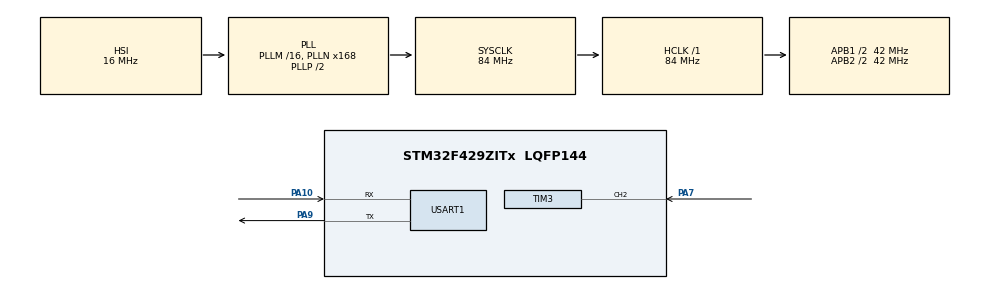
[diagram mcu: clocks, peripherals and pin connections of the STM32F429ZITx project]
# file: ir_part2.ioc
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Mcu.Family=STM32F4
Mcu.Name=STM32F429ZITx
Mcu.Package=LQFP144
NVIC.PriorityGroup=NVIC_PRIORITYGROUP_4
NVIC.TIM3_IRQn=true\:0\:0\:false\:false\:true\:true\:true
PA10.Mode=Asynchronous
PA10.Signal=USART1_RX
PA7.Signal=S_TIM3_CH2
PA9.Mode=Asynchronous
PA9.Signal=USART1_TX
ProjectManager.HeapSize=0x200
ProjectManager.StackSize=0x400
ProjectManager.TargetToolchain=MDK-ARM V5
RCC.48MHZClocksFreq_Value=42000000
RCC.AHBFreq_Value=84000000
RCC.APB1CLKDivider=RCC_HCLK_DIV2
RCC.APB1Freq_Value=42000000
RCC.APB1TimFreq_Value=84000000
RCC.APB2CLKDivider=RCC_HCLK_DIV2
RCC.APB2Freq_Value=42000000
RCC.APB2TimFreq_Value=84000000
RCC.CortexFreq_Value=84000000
RCC.HCLKFreq_Value=84000000
RCC.HSE_VALUE=25000000
RCC.HSI_VALUE=16000000
RCC.LSE_VALUE=32768
RCC.PLLN=168
RCC.SYSCLKFreq_VALUE=84000000
RCC.SYSCLKSource=RCC_SYSCLKSOURCE_PLLCLK
RCC.VCOOutputFreq_Value=168000000
SH.S_TIM3_CH2.0=TIM3_CH2,Input_Capture2_from_TI2
TIM3.Channel-Input_Capture2_from_TI2=TIM_CHANNEL_2
TIM3.ICPolarity_CH2=TIM_INPUTCHANNELPOLARITY_BOTHEDGE
TIM3.Period=65535
TIM3.Prescaler=83
TIM4.Prescaler=83
USART1.VirtualMode=VM_ASYNC
VP_TIM3_VS_ClockSourceINT.Mode=Internal
VP_TIM4_VS_ClockSourceINT.Mode=Internal
board=custom

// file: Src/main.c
/* USER CODE BEGIN Header */
/**
  ******************************************************************************
  * @file           : main.c
  * @brief          : Main program body
  ******************************************************************************
  * @attention
  *
  * <h2><center>&copy; Copyright (c) 2020 STMicroelectronics.
  * All rights reserved.</center></h2>
  *
  * This software component is licensed by ST under BSD 3-Clause license,
  * the "License"; You may not use this file except in compliance with the
  * License. You may obtain a copy of the License at:
  *                        opensource.org/licenses/BSD-3-Clause
  *
  ******************************************************************************
  */
/* USER CODE END Header */

#include "main.h"

/* USER CODE BEGIN Includes */
#include <string.h>
#include <stdio.h>
/* USER CODE END Includes */

/* USER CODE BEGIN PTD */
#define usTIM TIM4
/* USER CODE END PTD */

TIM_HandleTypeDef htim3;
TIM_HandleTypeDef htim4;

UART_HandleTypeDef huart1;

void SystemClock_Config(void);
static void MX_GPIO_Init(void);
static void MX_TIM3_Init(void);
static void MX_TIM4_Init(void);
static void MX_USART1_UART_Init(void);
/* USER CODE BEGIN PFP */
void usDelay(uint32_t uSec);
/* USER CODE END PFP */

/* USER CODE BEGIN 0 */
uint8_t icFlag = 0;
uint8_t captureIdx=0;
uint32_t edge1Time=0, edge2Time=0;

const float speedOfSound = 0.0343/2;
float distance;

char uartBuf[100];
/* USER CODE END 0 */

int main(void)
                                                                                                                                                                                                       {

  /* MCU Configuration--------------------------------------------------------*/

  /* Reset of all peripherals, Initializes the Flash interface and the Systick. */
  HAL_Init();

  /* Configure the system clock */
  SystemClock_Config();

  /* Initialize all configured peripherals */
  MX_GPIO_Init();
  MX_TIM3_Init();
  MX_TIM4_Init();
  MX_USART1_UART_Init();

  /* Infinite loop */
  while (1)
  {

    /* USER CODE BEGIN 3 */

		HAL_TIM_IC_Start_IT(&htim3, TIM_CHANNEL_2);

		uint32_t startTick = HAL_GetTick();
		do
		{
			if(icFlag) break;
		}while((HAL_GetTick() - startTick) < 500);  //500ms
		icFlag = 0;
		HAL_TIM_IC_Stop_IT(&htim3, TIM_CHANNEL_2);

		if(edge2Time > edge1Time)
		{
			distance = (edge2Time - edge1Time) + 0.0f;
		}
		else
		{
			distance = 0.0f;
		}

		//Print to UART terminal for debugging
		sprintf(uartBuf, "Distance (cm)  = %.1f\r\n", distance);
		HAL_UART_Transmit(&huart1, (uint8_t *)uartBuf, strlen(uartBuf), 100);

		HAL_Delay(1000);
  }
  /* USER CODE END 3 */
}

void SystemClock_Config(void)
{
  RCC_OscInitTypeDef RCC_OscInitStruct = {0};
  RCC_ClkInitTypeDef RCC_ClkInitStruct = {0};

  /** Configure the main internal regulator output voltage
  */
  __HAL_RCC_PWR_CLK_ENABLE();
  __HAL_PWR_VOLTAGESCALING_CONFIG(PWR_REGULATOR_VOLTAGE_SCALE3);
  /** Initializes the CPU, AHB and APB busses clocks
  */
  RCC_OscInitStruct.OscillatorType = RCC_OSCILLATORTYPE_HSI;
  RCC_OscInitStruct.HSIState = RCC_HSI_ON;
  RCC_OscInitStruct.HSICalibrationValue = RCC_HSICALIBRATION_DEFAULT;
  RCC_OscInitStruct.PLL.PLLState = RCC_PLL_ON;
  RCC_OscInitStruct.PLL.PLLSource = RCC_PLLSOURCE_HSI;
  RCC_OscInitStruct.PLL.PLLM = 16;
  RCC_OscInitStruct.PLL.PLLN = 168;
  RCC_OscInitStruct.PLL.PLLP = RCC_PLLP_DIV2;
  RCC_OscInitStruct.PLL.PLLQ = 4;
  if (HAL_RCC_OscConfig(&RCC_OscInitStruct) != HAL_OK)
  {
    Error_Handler();
  }
  /** Initializes the CPU, AHB and APB busses clocks
  */
  RCC_ClkInitStruct.ClockType = RCC_CLOCKTYPE_HCLK|RCC_CLOCKTYPE_SYSCLK
                              |RCC_CLOCKTYPE_PCLK1|RCC_CLOCKTYPE_PCLK2;
  RCC_ClkInitStruct.SYSCLKSource = RCC_SYSCLKSOURCE_PLLCLK;
  RCC_ClkInitStruct.AHBCLKDivider = RCC_SYSCLK_DIV1;
  RCC_ClkInitStruct.APB1CLKDivider = RCC_HCLK_DIV2;
  RCC_ClkInitStruct.APB2CLKDivider = RCC_HCLK_DIV2;

  if (HAL_RCC_ClockConfig(&RCC_ClkInitStruct, FLASH_LATENCY_2) != HAL_OK)
  {
    Error_Handler();
  }
}

static void MX_TIM3_Init(void)
{

  TIM_ClockConfigTypeDef sClockSourceConfig = {0};
  TIM_MasterConfigTypeDef sMasterConfig = {0};
  TIM_IC_InitTypeDef sConfigIC = {0};

  htim3.Instance = TIM3;
  htim3.Init.Prescaler = 83;
  htim3.Init.CounterMode = TIM_COUNTERMODE_UP;
  htim3.Init.Period = 65535;
  htim3.Init.ClockDivision = TIM_CLOCKDIVISION_DIV1;
  htim3.Init.AutoReloadPreload = TIM_AUTORELOAD_PRELOAD_DISABLE;
  if (HAL_TIM_Base_Init(&htim3) != HAL_OK)
  {
    Error_Handler();
  }
  sClockSourceConfig.ClockSource = TIM_CLOCKSOURCE_INTERNAL;
  if (HAL_TIM_ConfigClockSource(&htim3, &sClockSourceConfig) != HAL_OK)
  {
    Error_Handler();
  }
  if (HAL_TIM_IC_Init(&htim3) != HAL_OK)
  {
    Error_Handler();
  }
  sMasterConfig.MasterOutputTrigger = TIM_TRGO_RESET;
  sMasterConfig.MasterSlaveMode = TIM_MASTERSLAVEMODE_DISABLE;
  if (HAL_TIMEx_MasterConfigSynchronization(&htim3, &sMasterConfig) != HAL_OK)
  {
    Error_Handler();
  }
  sConfigIC.ICPolarity = TIM_INPUTCHANNELPOLARITY_BOTHEDGE;
  sConfigIC.ICSelection = TIM_ICSELECTION_DIRECTTI;
  sConfigIC.ICPrescaler = TIM_ICPSC_DIV1;
  sConfigIC.ICFilter = 0;
  if (HAL_TIM_IC_ConfigChannel(&htim3, &sConfigIC, TIM_CHANNEL_2) != HAL_OK)
  {
    Error_Handler();
  }

}

static void MX_TIM4_Init(void)
{

  TIM_ClockConfigTypeDef sClockSourceConfig = {0};
  TIM_MasterConfigTypeDef sMasterConfig = {0};

  htim4.Instance = TIM4;
  htim4.Init.Prescaler = 83;
  htim4.Init.CounterMode = TIM_COUNTERMODE_UP;
  htim4.Init.Period = 0;
  htim4.Init.ClockDivision = TIM_CLOCKDIVISION_DIV1;
  htim4.Init.AutoReloadPreload = TIM_AUTORELOAD_PRELOAD_DISABLE;
  if (HAL_TIM_Base_Init(&htim4) != HAL_OK)
  {
    Error_Handler();
  }
  sClockSourceConfig.ClockSource = TIM_CLOCKSOURCE_INTERNAL;
  if (HAL_TIM_ConfigClockSource(&htim4, &sClockSourceConfig) != HAL_OK)
  {
    Error_Handler();
  }
  sMasterConfig.MasterOutputTrigger = TIM_TRGO_RESET;
  sMasterConfig.MasterSlaveMode = TIM_MASTERSLAVEMODE_DISABLE;
  if (HAL_TIMEx_MasterConfigSynchronization(&htim4, &sMasterConfig) != HAL_OK)
  {
    Error_Handler();
  }

}

static void MX_USART1_UART_Init(void)
{

  huart1.Instance = USART1;
  huart1.Init.BaudRate = 115200;
  huart1.Init.WordLength = UART_WORDLENGTH_8B;
  huart1.Init.StopBits = UART_STOPBITS_1;
  huart1.Init.Parity = UART_PARITY_NONE;
  huart1.Init.Mode = UART_MODE_TX_RX;
  huart1.Init.HwFlowCtl = UART_HWCONTROL_NONE;
  huart1.Init.OverSampling = UART_OVERSAMPLING_16;
  if (HAL_UART_Init(&huart1) != HAL_OK)
  {
    Error_Handler();
  }

}

static void MX_GPIO_Init(void)
{

  /* GPIO Ports Clock Enable */
  __HAL_RCC_GPIOA_CLK_ENABLE();

}

/* USER CODE BEGIN 4 */
void usDelay(uint32_t uSec)
{
	if(uSec < 2) uSec = 2;
	usTIM->ARR = uSec - 1; 	/*sets the value in the auto-reload register*/
	usTIM->EGR = 1; 			/*Re-initialises the timer*/
	usTIM->SR &= ~1; 		//Resets the flag
	usTIM->CR1 |= 1; 		//Enables the counter
	while((usTIM->SR&0x0001) != 1);
	usTIM->SR &= ~(0x0001);
}

void HAL_TIM_IC_CaptureCallback(TIM_HandleTypeDef *htim)
{

		if(captureIdx == 0) //Fisrt edge
		{
			edge1Time = HAL_TIM_ReadCapturedValue(htim, TIM_CHANNEL_2); //__HAL_TIM_GetCounter(&htim3);//

			captureIdx = 1;
		}
		else if(captureIdx == 1)
		{
			edge2Time = HAL_TIM_ReadCapturedValue(htim, TIM_CHANNEL_2);
			captureIdx = 0;
			icFlag = 1;
		}
}
/* USER CODE END 4 */

void Error_Handler(void)
{
}

/************************ (C) COPYRIGHT STMicroelectronics *****END OF FILE****/
